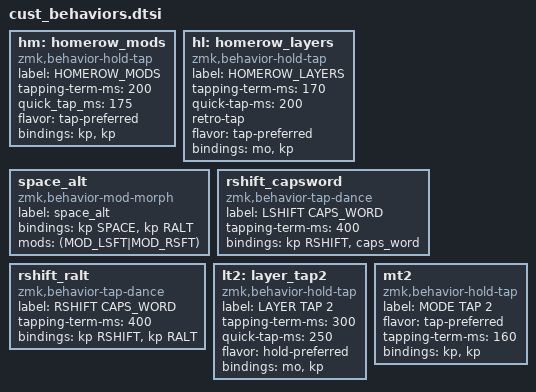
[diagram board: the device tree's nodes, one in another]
hm: homerow_mods {
    compatible = "zmk,behavior-hold-tap";
    label = "HOMEROW_MODS";
    #binding-cells = <2>;
    tapping-term-ms = <200>;
    quick_tap_ms = <175>;
    flavor = "tap-preferred";
    bindings = <&kp>, <&kp>;
};

hl: homerow_layers {
    compatible = "zmk,behavior-hold-tap";
    label = "HOMEROW_LAYERS";
    #binding-cells = <2>;
    tapping-term-ms = <170>;
    quick-tap-ms = <200>;
    // quick_tap_ms = <175>;
    // global-quick-tap;
    // flavor = "balanced";
    retro-tap;
    flavor = "tap-preferred";
    bindings = <&mo>, <&kp>;
};

space_alt: space_alt {
  compatible = "zmk,behavior-mod-morph";
  label = "space_alt";
  #binding-cells = <0>;
  bindings = <&kp SPACE>, <&kp RALT>;
  mods = <(MOD_LSFT|MOD_RSFT)>;
};

rshift_capsword: rshift_capsword {
    compatible = "zmk,behavior-tap-dance";
    label = "LSHIFT CAPS_WORD";
    #binding-cells = <0>;
    tapping-term-ms = <400>;
    bindings = <&kp RSHIFT>, <&caps_word>;
};

rshift_ralt: rshift_ralt {
    compatible = "zmk,behavior-tap-dance";
    label = "RSHIFT CAPS_WORD";
    #binding-cells = <0>;
    tapping-term-ms = <400>;
    bindings = <&kp RSHIFT>, <&kp RALT>;
};

lt2: layer_tap2 {
    compatible = "zmk,behavior-hold-tap";
    label = "LAYER TAP 2";
    #binding-cells = <2>;
    tapping-term-ms = <300>;
    quick-tap-ms = <250>;
    flavor = "hold-preferred";
    bindings = <&mo>, <&kp>;
};

mt2: mt2 {
    compatible = "zmk,behavior-hold-tap";
    label = "MODE TAP 2";
    #binding-cells = <2>;
    flavor = "tap-preferred";
    tapping-term-ms = <160>;
    bindings = <&kp>, <&kp>;
};

/*
del_layer: del_layer {
    compatible = "zmk,behavior-tap-dance";
    label = "DEL LAYER";
    #binding-cells = <0>;
    tapping-term-ms = <500>;
    bindings = <&mo ACT>, <&kp DEL>;
};
*/
